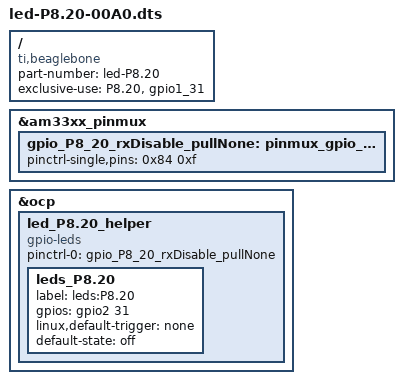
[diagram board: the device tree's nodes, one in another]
/*
* Easy gpio mux control of "P8.20" ("gpio1_31")
*/
/dts-v1/;
/plugin/;

/ {
	compatible = "ti,beaglebone", "ti,beaglebone-black";

	/* identification */
	part-number = "led-P8.20";
	/* version = "00A0"; */

	/* state the resources this cape uses */
	exclusive-use =
		/* the pin header uses */
		"P8.20",

		/* the hardware IP uses */
		"gpio1_31";
	
	
	/* rxDisable_pullNone state */
	fragment@0 {
		target = <&am33xx_pinmux>;
		__overlay__ {
			gpio_P8_20_rxDisable_pullNone: pinmux_gpio_P8.20_rxDisable_pullNone {
				pinctrl-single,pins = <
					0x84 0xf
				>;
			};
		};
	};

	fragment@1 {
		target = <&ocp>;
		__overlay__ {
			led_P8.20_helper {
				compatible = "gpio-leds";
				pinctrl-names = "default";
				pinctrl-0 = <&gpio_P8_20_rxDisable_pullNone>;
				
				leds_P8.20 {
					label = "leds:P8.20";
					gpios = <&gpio2 31 0>;
					linux,default-trigger = "none";
					default-state = "off";
				};
			};
			
		};
	};

};
